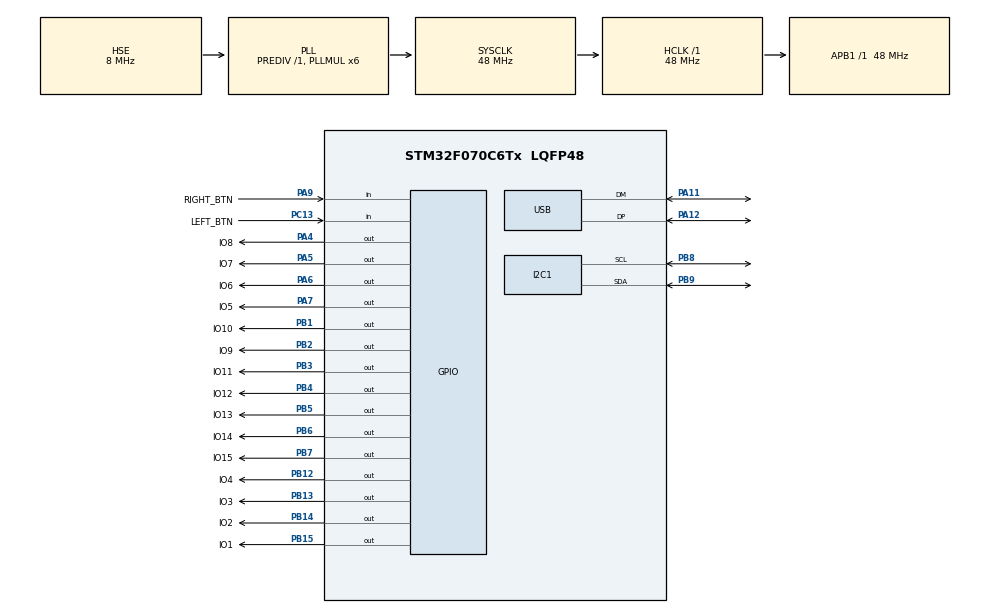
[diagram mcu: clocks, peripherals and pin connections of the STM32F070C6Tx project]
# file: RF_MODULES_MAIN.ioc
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I2C1.Timing=0x00201D2B
Mcu.Family=STM32F0
Mcu.Name=STM32F070C6Tx
Mcu.Package=LQFP48
NVIC.USB_IRQn=true\:0\:0\:false\:false\:true\:false\:true\:true
PA11.Mode=Device
PA11.Signal=USB_DM
PA12.Mode=Device
PA12.Signal=USB_DP
PA13.Mode=Serial_Wire
PA13.Signal=SYS_SWDIO
PA14.Mode=Serial_Wire
PA14.Signal=SYS_SWCLK
PA4.GPIO_Label=IO8
PA4.Signal=GPIO_Output
PA5.GPIO_Label=IO7
PA5.Signal=GPIO_Output
PA6.GPIO_Label=IO6
PA6.Signal=GPIO_Output
PA7.GPIO_Label=IO5
PA7.Signal=GPIO_Output
PA9.GPIO_Label=RIGHT_BTN
PA9.GPIO_PuPd=GPIO_PULLDOWN
PA9.Signal=GPIO_Input
PB1.GPIO_Label=IO10
PB1.Signal=GPIO_Output
PB12.GPIO_Label=IO4
PB12.Signal=GPIO_Output
PB13.GPIO_Label=IO3
PB13.Signal=GPIO_Output
PB14.GPIO_Label=IO2
PB14.Signal=GPIO_Output
PB15.GPIO_Label=IO1
PB15.Signal=GPIO_Output
PB2.GPIO_Label=IO9
PB2.Signal=GPIO_Output
PB3.GPIO_Label=IO11
PB3.Signal=GPIO_Output
PB4.GPIO_Label=IO12
PB4.Signal=GPIO_Output
PB5.GPIO_Label=IO13
PB5.Signal=GPIO_Output
PB6.GPIO_Label=IO14
PB6.Signal=GPIO_Output
PB7.GPIO_Label=IO15
PB7.Signal=GPIO_Output
PB8.Mode=I2C
PB8.Signal=I2C1_SCL
PB9.Mode=I2C
PB9.Signal=I2C1_SDA
PC13.GPIO_Label=LEFT_BTN
PC13.GPIO_PuPd=GPIO_PULLDOWN
PC13.Signal=GPIO_Input
PF0-OSC_IN.Mode=HSE-External-Oscillator
PF0-OSC_IN.Signal=RCC_OSC_IN
PF1-OSC_OUT.Mode=HSE-External-Oscillator
PF1-OSC_OUT.Signal=RCC_OSC_OUT
ProjectManager.HeapSize=0x000
ProjectManager.StackSize=0x400
ProjectManager.TargetToolchain=STM32CubeIDE
RCC.AHBFreq_Value=48000000
RCC.APB1Freq_Value=48000000
RCC.APB1TimFreq_Value=48000000
RCC.HCLKFreq_Value=48000000
RCC.PLLMUL=RCC_PLL_MUL6
RCC.SYSCLKFreq_VALUE=48000000
RCC.SYSCLKSource=RCC_SYSCLKSOURCE_PLLCLK
USB_DEVICE.APP_TX_DATA_SIZE=64
USB_DEVICE.CLASS_NAME_FS=CDC
USB_DEVICE.VirtualMode=Cdc
USB_DEVICE.VirtualModeFS=Cdc_FS
VP_USB_DEVICE_VS_USB_DEVICE_CDC_FS.Mode=CDC_FS
board=custom

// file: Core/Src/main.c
/* USER CODE BEGIN Header */
/**
  ******************************************************************************
  * @file           : main.c
  * @brief          : Main program body
  ******************************************************************************
  * @attention
  *
  * Copyright (c) 2026 STMicroelectronics.
  * All rights reserved.
  *
  * This software is licensed under terms that can be found in the LICENSE file
  * in the root directory of this software component.
  * If no LICENSE file comes with this software, it is provided AS-IS.
  *
  ******************************************************************************
  */
/* USER CODE END Header */
#include "main.h"
#include "usb_device.h"

/* USER CODE BEGIN Includes */

#include "hw.h"
#include "rf_modules.h"
#include "ssd1306_conf.h"
/* USER CODE END Includes */

I2C_HandleTypeDef hi2c1;

void SystemClock_Config(void);
static void MX_GPIO_Init(void);
static void MX_I2C1_Init(void);

int main(void)
{

  /* MCU Configuration--------------------------------------------------------*/

  /* Reset of all peripherals, Initializes the Flash interface and the Systick. */
  HAL_Init();

  /* Configure the system clock */
  SystemClock_Config();

  /* Initialize all configured peripherals */
  MX_GPIO_Init();
  MX_I2C1_Init();
  MX_USB_DEVICE_Init();

  /* Infinite loop */
  /* USER CODE BEGIN WHILE */
  bool DisplayPresent = false;

  if(HAL_I2C_IsDeviceReady(&hi2c1, SSD1306_I2C_ADDR, 3, 100) == HAL_OK) {

	  DisplayPresent = true;
      HW_Init();
      HW_PlayBootAnimation();

   }

  // SELECT THE ACTIVE MODULE HERE:
  /*
  ATEK1801    — Tunable LPF (CTRL1–5)
  ATEK1601    — Switchable Filterbank (CTRLA/B/C, negative voltage –5V)
  ATEK1231    — 5-bit Attenuator (P1–P5)                    — HW not ready
  ATEK1001    — Switchable Filter Bank (CTRLA/B/C)          — HW not ready
  ATEK1202    — SPDT Switch (1 CTRL pin, HIGH/LOW)          — HW not ready
  ATEK_PS_TBD — Analog Phase Shifter (DAC, 0–10V)           — HW not ready, module name TBD
  */

  RF_Init(ATEK1601);
  while (1)
  {
    /* USER CODE END WHILE */

    /* USER CODE BEGIN 3 */
	  RF_HandleButtons();
	  RF_ProcessSerialCommand();
	  RF_Update();
	  HAL_Delay(10);
  }
  /* USER CODE END 3 */
}

void SystemClock_Config(void)
{
  RCC_OscInitTypeDef RCC_OscInitStruct = {0};
  RCC_ClkInitTypeDef RCC_ClkInitStruct = {0};
  RCC_PeriphCLKInitTypeDef PeriphClkInit = {0};

  /** Initializes the RCC Oscillators according to the specified parameters
  * in the RCC_OscInitTypeDef structure.
  */
  RCC_OscInitStruct.OscillatorType = RCC_OSCILLATORTYPE_HSI|RCC_OSCILLATORTYPE_HSE;
  RCC_OscInitStruct.HSEState = RCC_HSE_ON;
  RCC_OscInitStruct.HSIState = RCC_HSI_ON;
  RCC_OscInitStruct.HSICalibrationValue = RCC_HSICALIBRATION_DEFAULT;
  RCC_OscInitStruct.PLL.PLLState = RCC_PLL_ON;
  RCC_OscInitStruct.PLL.PLLSource = RCC_PLLSOURCE_HSE;
  RCC_OscInitStruct.PLL.PLLMUL = RCC_PLL_MUL6;
  RCC_OscInitStruct.PLL.PREDIV = RCC_PREDIV_DIV1;
  if (HAL_RCC_OscConfig(&RCC_OscInitStruct) != HAL_OK)
  {
    Error_Handler();
  }

  /** Initializes the CPU, AHB and APB buses clocks
  */
  RCC_ClkInitStruct.ClockType = RCC_CLOCKTYPE_HCLK|RCC_CLOCKTYPE_SYSCLK
                              |RCC_CLOCKTYPE_PCLK1;
  RCC_ClkInitStruct.SYSCLKSource = RCC_SYSCLKSOURCE_PLLCLK;
  RCC_ClkInitStruct.AHBCLKDivider = RCC_SYSCLK_DIV1;
  RCC_ClkInitStruct.APB1CLKDivider = RCC_HCLK_DIV1;

  if (HAL_RCC_ClockConfig(&RCC_ClkInitStruct, FLASH_LATENCY_1) != HAL_OK)
  {
    Error_Handler();
  }
  PeriphClkInit.PeriphClockSelection = RCC_PERIPHCLK_USB|RCC_PERIPHCLK_I2C1;
  PeriphClkInit.I2c1ClockSelection = RCC_I2C1CLKSOURCE_HSI;
  PeriphClkInit.UsbClockSelection = RCC_USBCLKSOURCE_PLL;

  if (HAL_RCCEx_PeriphCLKConfig(&PeriphClkInit) != HAL_OK)
  {
    Error_Handler();
  }
}

static void MX_I2C1_Init(void)
{

  hi2c1.Instance = I2C1;
  hi2c1.Init.Timing = 0x00201D2B;
  hi2c1.Init.OwnAddress1 = 0;
  hi2c1.Init.AddressingMode = I2C_ADDRESSINGMODE_7BIT;
  hi2c1.Init.DualAddressMode = I2C_DUALADDRESS_DISABLE;
  hi2c1.Init.OwnAddress2 = 0;
  hi2c1.Init.OwnAddress2Masks = I2C_OA2_NOMASK;
  hi2c1.Init.GeneralCallMode = I2C_GENERALCALL_DISABLE;
  hi2c1.Init.NoStretchMode = I2C_NOSTRETCH_DISABLE;
  if (HAL_I2C_Init(&hi2c1) != HAL_OK)
  {
    Error_Handler();
  }

  /** Configure Analogue filter
  */
  if (HAL_I2CEx_ConfigAnalogFilter(&hi2c1, I2C_ANALOGFILTER_ENABLE) != HAL_OK)
  {
    Error_Handler();
  }

  /** Configure Digital filter
  */
  if (HAL_I2CEx_ConfigDigitalFilter(&hi2c1, 0) != HAL_OK)
  {
    Error_Handler();
  }

}

static void MX_GPIO_Init(void)
{
  GPIO_InitTypeDef GPIO_InitStruct = {0};

  /* GPIO Ports Clock Enable */
  __HAL_RCC_GPIOC_CLK_ENABLE();
  __HAL_RCC_GPIOF_CLK_ENABLE();
  __HAL_RCC_GPIOA_CLK_ENABLE();
  __HAL_RCC_GPIOB_CLK_ENABLE();

  /*Configure GPIO pin Output Level */
  HAL_GPIO_WritePin(GPIOA, IO8_Pin|IO7_Pin|IO6_Pin|IO5_Pin, GPIO_PIN_RESET);

  /*Configure GPIO pin Output Level */
  HAL_GPIO_WritePin(GPIOB, IO10_Pin|IO9_Pin|IO4_Pin|IO3_Pin
                          |IO2_Pin|IO1_Pin|IO11_Pin|IO12_Pin
                          |IO13_Pin|IO14_Pin|IO15_Pin, GPIO_PIN_RESET);

  /*Configure GPIO pin : LEFT_BTN_Pin */
  GPIO_InitStruct.Pin = LEFT_BTN_Pin;
  GPIO_InitStruct.Mode = GPIO_MODE_INPUT;
  GPIO_InitStruct.Pull = GPIO_PULLDOWN;
  HAL_GPIO_Init(LEFT_BTN_GPIO_Port, &GPIO_InitStruct);

  /*Configure GPIO pins : IO8_Pin IO7_Pin IO6_Pin IO5_Pin */
  GPIO_InitStruct.Pin = IO8_Pin|IO7_Pin|IO6_Pin|IO5_Pin;
  GPIO_InitStruct.Mode = GPIO_MODE_OUTPUT_PP;
  GPIO_InitStruct.Pull = GPIO_NOPULL;
  GPIO_InitStruct.Speed = GPIO_SPEED_FREQ_LOW;
  HAL_GPIO_Init(GPIOA, &GPIO_InitStruct);

  /*Configure GPIO pins : IO10_Pin IO9_Pin IO4_Pin IO3_Pin
                           IO2_Pin IO1_Pin IO11_Pin IO12_Pin
                           IO13_Pin IO14_Pin IO15_Pin */
  GPIO_InitStruct.Pin = IO10_Pin|IO9_Pin|IO4_Pin|IO3_Pin
                          |IO2_Pin|IO1_Pin|IO11_Pin|IO12_Pin
                          |IO13_Pin|IO14_Pin|IO15_Pin;
  GPIO_InitStruct.Mode = GPIO_MODE_OUTPUT_PP;
  GPIO_InitStruct.Pull = GPIO_NOPULL;
  GPIO_InitStruct.Speed = GPIO_SPEED_FREQ_LOW;
  HAL_GPIO_Init(GPIOB, &GPIO_InitStruct);

  /*Configure GPIO pin : RIGHT_BTN_Pin */
  GPIO_InitStruct.Pin = RIGHT_BTN_Pin;
  GPIO_InitStruct.Mode = GPIO_MODE_INPUT;
  GPIO_InitStruct.Pull = GPIO_PULLDOWN;
  HAL_GPIO_Init(RIGHT_BTN_GPIO_Port, &GPIO_InitStruct);

}

void Error_Handler(void)
{
  __disable_irq();
  while (1)
  {
  }
}
